# STM32F373xC register map
File version: 1.0
Registers are 32-bit, read-write, reset 0x0 unless marked. A register's access mark holds for its fields unless they carry their own. Offsets are from the block's base; [hi:lo] are bit positions; {n}, {i} and the like mark numbered series; 'fields as' and 'values as' point back to an identical list.

## RCC — Reset and Clock Control
Base 0x40021000
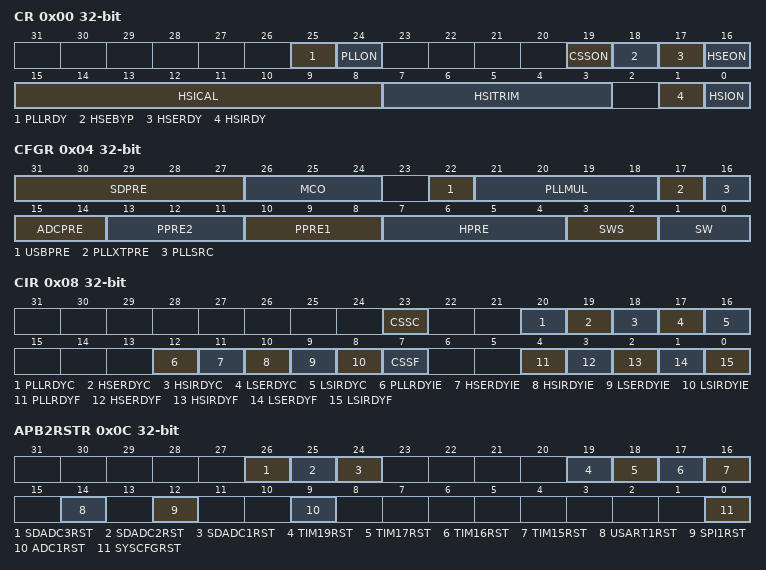
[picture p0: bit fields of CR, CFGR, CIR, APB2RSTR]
0x00 CR — RCC clock control register
  [25] PLLRDY, [24] PLLON, [19] CSSON, [18] HSEBYP, [17] HSERDY, [16] HSEON, [15:8] HSICAL, [7:3] HSITRIM, [1] HSIRDY, [0] HSION
0x04 CFGR — RCC clock configuration register
  [31:27] SDPRE — SDPRE[4:0] bits (Sigma Delta ADC prescaler)
    0=DIV_1 (SDADC CLK not divided); 16=DIV_2 (SDADC CLK divided by 2); 17=DIV_4 (SDADC CLK divided by 4); 18=DIV_6 (SDADC CLK divided by 6); 19=DIV_8 (SDADC CLK divided by 8); 20=DIV_10 (SDADC CLK divided by 10); 21=DIV_12 (SDADC CLK divided by 12); 22=DIV_14 (SDADC CLK divided by 14); 23=DIV_16 (SDADC CLK divided by 16); 24=DIV_20 (SDADC CLK divided by 20); 25=DIV_24 (SDADC CLK divided by 24); 26=DIV_28 (SDADC CLK divided by 28); 27=DIV_32 (SDADC CLK divided by 32); 28=DIV_36 (SDADC CLK divided by 36); 29=DIV_40 (SDADC CLK divided by 40); 30=DIV_44 (SDADC CLK divided by 44); 31=DIV_48 (SDADC CLK divided by 48)
  [26:24] MCO — MCO[2:0] bits (Microcontroller Clock Output)
  [22] USBPRE — USB prescaler
    1=PLL (USB prescaler is PLL clock divided by 1); 0=DIV_1_5 (USB prescaler is PLL clock divided by 1.5)
  [21:18] PLLMUL — PLLMUL[3:0] bits (PLL multiplication factor)
    {v}=MUL_{v+2} (PLL input clock*{v+2}) (v=0..14)
  [17] PLLXTPRE — HSE divider for PLL entry
  [16] PLLSRC — PLL entry clock source
    0=NONE (No clock selected as main PLL entry clock source); 1=HSE (HSE/PREDIV clock selected as PLL entry clock source)
  [15:14] ADCPRE
    0=DIV_2 (ADC prescaler PCLK divided by 2); 1=DIV_4 (ADC prescaler PCLK divided by 4); 2=DIV_6 (ADC prescaler PCLK divided by 6); 3=DIV_8 (ADC prescaler PCLK divided by 8)
  [13:11] PPRE2 — PRE2[2:0] bits (APB2 prescaler)
    0=DIV_1 (HCLK not divided); 4=DIV_2 (HCLK divided by 2); 5=DIV_4 (HCLK divided by 4); 6=DIV_8 (HCLK divided by 8); 7=DIV_16 (HCLK divided by 16)
  [10:8] PPRE1 — PRE1[2:0] bits (APB1 prescaler)
    values as PPRE2
  [7:4] HPRE — HPRE[3:0] bits (AHB prescaler)
    0=DIV_1 (SYSCLK not divided); 8=DIV_2 (SYSCLK divided by 2); 9=DIV_4 (SYSCLK divided by 4); 10=DIV_8 (SYSCLK divided by 8); 11=DIV_16 (SYSCLK divided by 16); 12=DIV_64 (SYSCLK divided by 64); 13=DIV_128 (SYSCLK divided by 128); 14=DIV_256 (SYSCLK divided by 256); 15=DIV_512 (SYSCLK divided by 512)
  [3:2] SWS — SWS[1:0] bits (System Clock Switch Status)
    0=HSI (HSI used as system clock); 1=HSE (HSE used as system clock); 2=PLL (PLL used as system clock)
  [1:0] SW — SW[1:0] bits (System clock Switch)
    0=HSI (HSI selection as system clock); 1=HSE (HSE selection as system clock); 2=PLL (PLL selection as system clock)
0x08 CIR — RCC clock interrupt register
  [23] CSSC — Clock Security System Interrupt Clear
  [20] PLLRDYC — PLL Ready Interrupt Clear
  [19] HSERDYC — HSE Ready Interrupt Clear
  [18] HSIRDYC — HSI Ready Interrupt Clear
  [17] LSERDYC — LSE Ready Interrupt Clear
  [16] LSIRDYC — LSI Ready Interrupt Clear
  [12] PLLRDYIE — PLL Ready Interrupt Enable
  [11] HSERDYIE — HSE Ready Interrupt Enable
  [10] HSIRDYIE — HSI Ready Interrupt Enable
  [9] LSERDYIE — LSE Ready Interrupt Enable
  [8] LSIRDYIE — LSI Ready Interrupt Enable
  [7] CSSF — Clock Security System Interrupt flag
  [4] PLLRDYF — PLL Ready Interrupt flag
  [3] HSERDYF — HSE Ready Interrupt flag
  [2] HSIRDYF — HSI Ready Interrupt flag
  [1] LSERDYF — LSE Ready Interrupt flag
  [0] LSIRDYF — LSI Ready Interrupt flag
0x0C APB2RSTR — RCC APB2 peripheral reset register
  [26] SDADC3RST — SDADC3 reset
  [25] SDADC2RST — SDADC2 reset
  [24] SDADC1RST — SDADC1 reset
  [19] TIM19RST — TIM19 reset
  [18] TIM17RST — TIM17 reset
  [17] TIM16RST — TIM16 reset
  [16] TIM15RST — TIM15 reset
  [14] USART1RST — USART1 reset
  [12] SPI1RST — SPI1 reset
  [9] ADC1RST — ADC1 reset
  [0] SYSCFGRST — SYSCFG reset
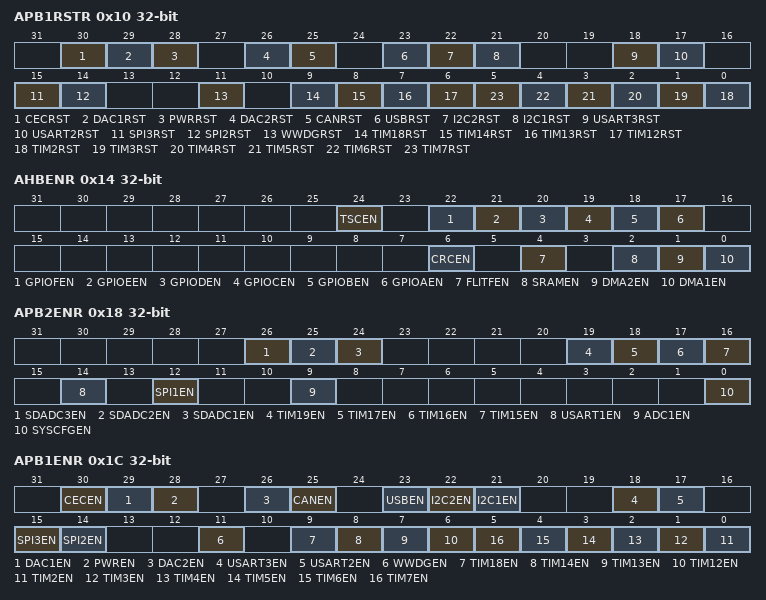
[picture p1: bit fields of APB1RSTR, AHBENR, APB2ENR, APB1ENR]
0x10 APB1RSTR — RCC APB1 peripheral reset register
  [30] CECRST — CEC reset
  [29] DAC1RST — DAC 1 reset
  [28] PWRRST — PWR reset
  [26] DAC2RST — DAC 2 reset
  [25] CANRST — CAN reset
  [23] USBRST — USB reset
  [22] I2C2RST — I2C 2 reset
  [21] I2C1RST — I2C 1 reset
  [18] USART3RST — USART 3 reset
  [17] USART2RST — USART 2 reset
  [15] SPI3RST — SPI3 reset
  [14] SPI2RST — SPI2 reset
  [11] WWDGRST — Window Watchdog reset
  [9] TIM18RST — Timer 18 reset
  [8] TIM14RST — Timer 14 reset
  [7] TIM13RST — Timer 13 reset
  [6] TIM12RST — Timer 12 reset
  [n-2] TIM{n}RST (n=2..7) — Timer {n} reset
0x14 AHBENR — RCC AHB peripheral clock register
  [24] TSCEN — TS clock enable
  [22] GPIOFEN — GPIOF clock enable
  [21] GPIOEEN — GPIOE clock enable
  [20] GPIODEN — GPIOD clock enable
  [19] GPIOCEN — GPIOC clock enable
  [18] GPIOBEN — GPIOB clock enable
  [17] GPIOAEN — GPIOA clock enable
  [6] CRCEN — CRC clock enable
  [4] FLITFEN — FLITF clock enable
  [2] SRAMEN — SRAM interface clock enable
  [1] DMA2EN — DMA2 clock enable
  [0] DMA1EN — DMA1 clock enable
0x18 APB2ENR — RCC APB2 peripheral clock enable register
  [26] SDADC3EN — SDADC3 clock enable
  [25] SDADC2EN — SDADC2 clock enable
  [24] SDADC1EN — SDADC1 clock enable
  [19] TIM19EN — TIM19 clock enable
  [18] TIM17EN — TIM17 clock enable
  [17] TIM16EN — TIM16 clock enable
  [16] TIM15EN — TIM15 clock enable
  [14] USART1EN — USART1 clock enable
  [12] SPI1EN — SPI1 clock enable
  [9] ADC1EN — ADC1 clock enable
  [0] SYSCFGEN — SYSCFG clock enable
0x1C APB1ENR — RCC APB1 peripheral clock enable register
  [30] CECEN — CEC clock enable
  [29] DAC1EN — DAC 1 clock enable
  [28] PWREN — PWR clock enable
  [26] DAC2EN — DAC 2 clock enable
  [25] CANEN — CAN clock enable
  [23] USBEN — USB clock enable
  [22] I2C2EN — I2C 2 clock enable
  [21] I2C1EN — I2C 1 clock enable
  [18] USART3EN — USART 3 clock enable
  [17] USART2EN — USART 2 clock enable
  [15] SPI3EN — SPI3 clock enable
  [14] SPI2EN — SPI2 clock enable
  [11] WWDGEN — Window Watchdog clock enable
  [9] TIM18EN — Timer 18 clock enable
  [8] TIM14EN — Timer 14 clock enable
  [7] TIM13EN — Timer 13 clock enable
  [6] TIM12EN — Timer 12 clock enable
  [n-2] TIM{n}EN (n=2..7) — Timer {n} clock enable
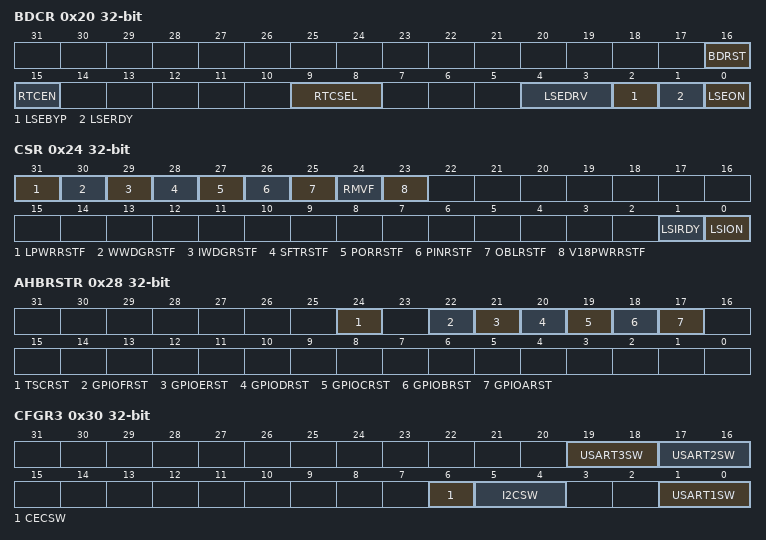
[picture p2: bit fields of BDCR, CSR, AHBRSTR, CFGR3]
0x20 BDCR — RCC Backup domain control register
  [16] BDRST — Backup domain software reset
  [15] RTCEN — RTC clock enable
  [9:8] RTCSEL — RTCSEL[1:0] bits (RTC clock source selection)
    0=NONE (No clock used as RTC clock); 1=LSE (LSE oscillator clock used as RTC clock); 2=LSI (LSI oscillator clock used as RTC clock); 3=HSE_DIV32 (HSE oscillator clock divided by 32 used as RTC clock)
  [4:3] LSEDRV — LSEDRV[1:0] bits (LSE Osc. drive capability)
    0=LOW (Xtal mode lower driving capability); 2=MEDIUMLOW (Xtal mode medium low driving capability); 1=MEDIUMHIGH (Xtal mode medium high driving capability); 3=HIGH (Xtal mode higher driving capability)
  [2] LSEBYP — External Low Speed oscillator Bypass
  [1] LSERDY — External Low Speed oscillator Ready
  [0] LSEON — External Low Speed oscillator enable
0x24 CSR — RCC clock control & status register
  [31] LPWRRSTF — Low-Power reset flag
  [30] WWDGRSTF — Window watchdog reset flag
  [29] IWDGRSTF — Independent Watchdog reset flag
  [28] SFTRSTF — Software Reset flag
  [27] PORRSTF — POR/PDR reset flag
  [26] PINRSTF — PIN reset flag
  [25] OBLRSTF — OBL reset flag
  [24] RMVF — Remove reset flag
  [23] V18PWRRSTF — V1.8 power domain reset flag
  [1] LSIRDY — Internal Low Speed oscillator Ready
  [0] LSION — Internal Low Speed oscillator enable
0x28 AHBRSTR — RCC AHB peripheral reset register
  [24] TSCRST — TSC reset
  [22] GPIOFRST — GPIOF reset
  [21] GPIOERST — GPIOE reset
  [20] GPIODRST — GPIOD reset
  [19] GPIOCRST — GPIOC reset
  [18] GPIOBRST — GPIOB reset
  [17] GPIOARST — GPIOA reset
0x2C CFGR2 — RCC clock configuration register 2
  [3:0] PREDIV — PREDIV[3:0] bits
    0=DIV_1 (PREDIV input clock not divided); {v}=DIV_{v+1} (PREDIV input clock divided by {v+1}) (v=1..15)
0x30 CFGR3 — RCC clock configuration register 3
  [19:18] USART3SW — USART3SW[1:0] bits
  [17:16] USART2SW — USART2SW[1:0] bits
  [6] CECSW — CECSW bits
    0=HSI_DIV244 (HSI clock divided by 244 selected as HDMI CEC entry clock source); 1=LSE (LSE clock selected as HDMI CEC entry clock source)
  [5:4] I2CSW — I2CSW bits
  [1:0] USART1SW — USART1SW[1:0] bits
